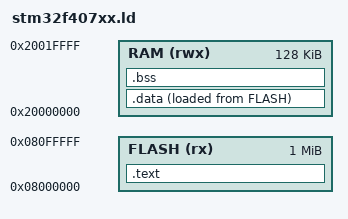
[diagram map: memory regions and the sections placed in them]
ENTRY(Reset_Handler)

MEMORY
{
    FLASH(rx) : ORIGIN = 0x08000000, LENGTH = 1024K
    RAM(rwx) : ORIGIN = 0X20000000, LENGTH = 128K
}    

__top_ram = ORIGIN(RAM) + LENGTH(RAM);

SECTIONS
{
    .text :
    {
        *(.isr_vector)
        *(.text*)
        *(.rodata*)
        . = ALIGN(4);
    } > FLASH

    . = ALIGN(4);
    _etext = .;
    
    .data :
    {
        _sdata = .;
        *(.data*)
        . = ALIGN(4);
        _edata = .;
    } > RAM AT > FLASH

    .bss :
    {
        _sbss = .;
        __bss_start__ = _sbss;
        *(.bss*)
        *(COMMON)
        . = ALIGN(4);
        _ebss = .;
        __bss_end__ = _ebss;
        . = ALIGN(4);
        end = .;
    } > RAM

    PROVIDE(_stack_top = __top_ram - 0);

}
